# STM8L052C6 register map
Vendor: STMicroelectronics; Series: STM8L/STM8AL, medium density; File version: 1.0
CPU: other r1p0, big endian, no MPU, no FPU, 4 interrupt priority bits
Registers are 8-bit, read-write, reset 0x0 unless marked. A register's access mark holds for its fields unless they carry their own. Offsets are from the block's base; [hi:lo] are bit positions; {n}, {i} and the like mark numbered series.

## ITC_SPR
Base 0x00007F70
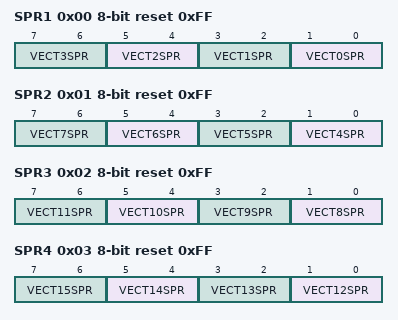
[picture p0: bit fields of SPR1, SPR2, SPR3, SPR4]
0x00 SPR1 reset 0xFF — Interrupt Software priority register 1
  [2n+1:2n] VECT{n}SPR (n=0..3)
0x01 SPR2 reset 0xFF — Interrupt Software priority register 2
  [2n-7:2n-8] VECT{n}SPR (n=4..7)
0x02 SPR3 reset 0xFF — Interrupt Software priority register 3
  [2n-15:2n-16] VECT{n}SPR (n=8..11)
0x03 SPR4 reset 0xFF — Interrupt Software priority register 4
  [2n-23:2n-24] VECT{n}SPR (n=12..15)
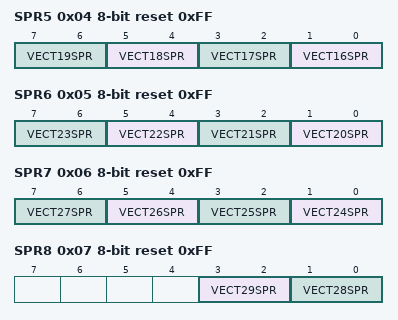
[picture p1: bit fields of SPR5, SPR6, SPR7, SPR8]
0x04 SPR5 reset 0xFF — Interrupt Software priority register 5
  [2n-31:2n-32] VECT{n}SPR (n=16..19)
0x05 SPR6 reset 0xFF — Interrupt Software priority register 6
  [2n-39:2n-40] VECT{n}SPR (n=20..23)
0x06 SPR7 reset 0xFF — Interrupt Software priority register 7
  [2n-47:2n-48] VECT{n}SPR (n=24..27)
0x07 SPR8 reset 0xFF — Interrupt Software priority register 8
  [3:2] VECT29SPR, [1:0] VECT28SPR

## IWDG
Base 0x000050E0
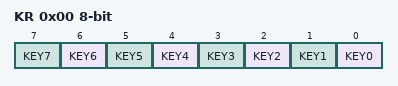
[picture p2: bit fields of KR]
0x00 KR — IWDG key register
  [n] KEY{n} (n=0..7)
0x01 PR — IWDG prescaler register
  [2:0] PR
0x02 RLR reset 0xFF — IWDG reload register
  [7:0] RL

## LCD
Base 0x00005400
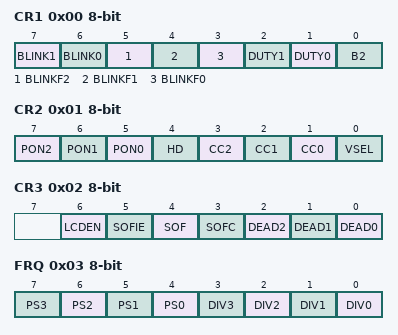
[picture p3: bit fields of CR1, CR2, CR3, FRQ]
0x00 CR1 — LCD control register 1
  [7] BLINK1, [6] BLINK0, [5] BLINKF2, [4] BLINKF1, [3] BLINKF0, [2] DUTY1, [1] DUTY0, [0] B2
0x01 CR2 — LCD control register 2
  [7] PON2, [6] PON1, [5] PON0, [4] HD, [3] CC2, [2] CC1, [1] CC0, [0] VSEL
0x02 CR3 — LCD control register 3
  [6] LCDEN, [5] SOFIE, [4] SOF, [3] SOFC, [2] DEAD2, [1] DEAD1, [0] DEAD0
0x03 FRQ — LCD frequency selection register
  [n+4] PS{n} (n=0..3), [n] DIV{n} (n=0..3)
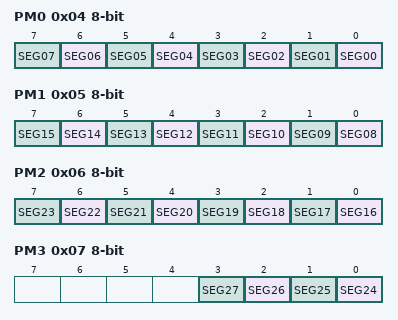
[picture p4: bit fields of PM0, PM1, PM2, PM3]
0x04 PM0 — LCD Port mask register 0
  [n] SEG{n:02} (n=0..7)
0x05 PM1 — LCD Port mask register 1
  [n-8] SEG{n:02} (n=8..15)
0x06 PM2 — LCD Port mask register 2
  [n-16] SEG{n} (n=16..23)
0x07 PM3 — LCD Port mask register 3
  [n-24] SEG{n} (n=24..27)
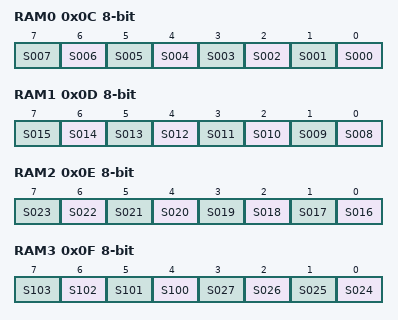
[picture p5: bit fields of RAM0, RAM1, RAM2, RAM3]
0x0C RAM0 — LCD display memory 0
  [n] S{n:03} (n=0..7)
0x0D RAM1 — LCD display memory 1
  [n-8] S{n:03} (n=8..15)
0x0E RAM2 — LCD display memory 2
  [n-16] S{n:03} (n=16..23)
0x0F RAM3 — LCD display memory 3
  [n-96] S{n} (n=100..103), [n-24] S{n:03} (n=24..27)
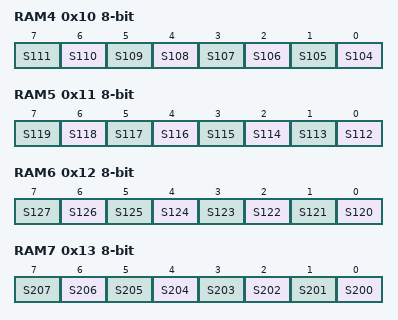
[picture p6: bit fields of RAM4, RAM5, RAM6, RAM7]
0x10 RAM4 — LCD display memory 4
  [n-104] S{n} (n=104..111)
0x11 RAM5 — LCD display memory 5
  [n-112] S{n} (n=112..119)
0x12 RAM6 — LCD display memory 6
  [n-120] S{n} (n=120..127)
0x13 RAM7 — LCD display memory 7
  [n-200] S{n} (n=200..207)
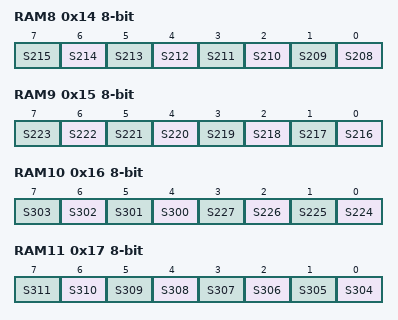
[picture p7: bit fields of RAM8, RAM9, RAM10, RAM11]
0x14 RAM8 — LCD display memory 8
  [n-208] S{n} (n=208..215)
0x15 RAM9 — LCD display memory 9
  [n-216] S{n} (n=216..223)
0x16 RAM10 — LCD display memory 10
  [n-296] S{n} (n=300..303), [n-224] S{n} (n=224..227)
0x17 RAM11 — LCD display memory 11
  [n-304] S{n} (n=304..311)
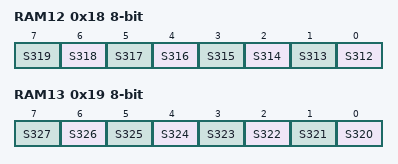
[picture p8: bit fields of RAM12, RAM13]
0x18 RAM12 — LCD display memory 12
  [n-312] S{n} (n=312..319)
0x19 RAM13 — LCD display memory 13
  [n-320] S{n} (n=320..327)

## OPT
Base 0x00004800
0x00 OPT0 reset 0xAA — Read-out protection (ROP)
0x02 OPT1 — User boot code (UBC)
0x08 OPT3 — Watchdog option
0x09 OPT4 — Clock option
0x0A OPT5 — Brownout reset (BOR)
0x0B OPTBL_H — Bootloader (high byte)
0x0C OPTBL_L — Bootloader (low byte)

## PWR
Base 0x000050B2
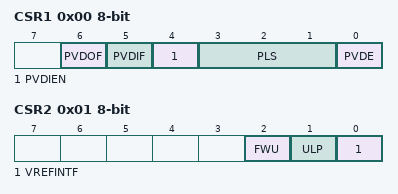
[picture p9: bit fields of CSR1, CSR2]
0x00 CSR1 — Power control and status register 1
  [6] PVDOF, [5] PVDIF, [4] PVDIEN, [3:1] PLS, [0] PVDE
0x01 CSR2 — Power control and status register 2
  [2] FWU, [1] ULP, [0] VREFINTF

## PORTA
Base 0x00005000
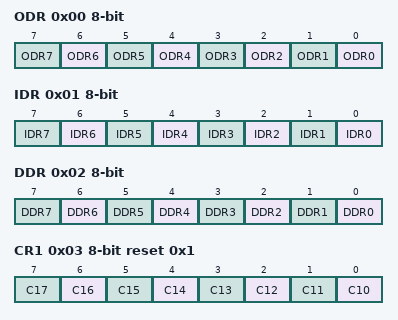
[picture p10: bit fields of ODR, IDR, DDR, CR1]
0x00 ODR — Port A data output latch register
  [n] ODR{n} (n=0..7)
0x01 IDR — Port A input pin value register
  [n] IDR{n} (n=0..7)
0x02 DDR — Port A data direction register
  [n] DDR{n} (n=0..7)
0x03 CR1 reset 0x1 — Port A control register 1
  [n-10] C{n} (n=10..17)
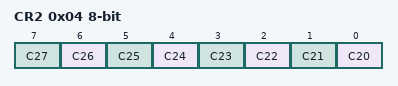
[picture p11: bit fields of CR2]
0x04 CR2 — Port A control register 2
  [n-20] C{n} (n=20..27)

## PORTB
Base 0x00005005
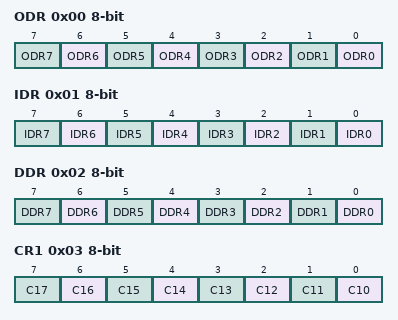
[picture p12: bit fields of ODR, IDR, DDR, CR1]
0x00 ODR — Port B data output latch register
  [n] ODR{n} (n=0..7)
0x01 IDR — Port B input pin value register
  [n] IDR{n} (n=0..7)
0x02 DDR — Port B data direction register
  [n] DDR{n} (n=0..7)
0x03 CR1 — Port B control register 1
  [n-10] C{n} (n=10..17)
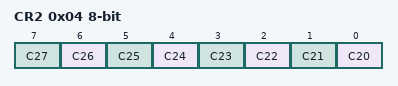
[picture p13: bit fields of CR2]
0x04 CR2 — Port B control register 2
  [n-20] C{n} (n=20..27)
